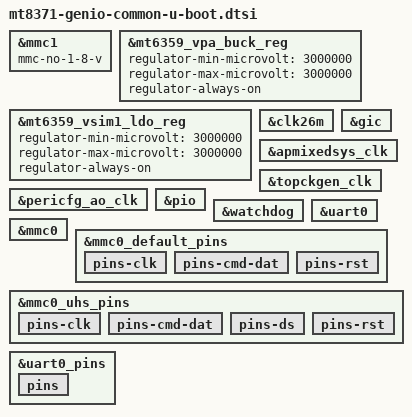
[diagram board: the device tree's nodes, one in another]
// SPDX-License-Identifier: (GPL-2.0-only OR MIT)
/*
 * Copyright (C) 2026 MediaTek Inc.
 */

&mmc1 {
	/* U-Boot driver doesn't support UHS yet. */
	/delete-property/ sd-uhs-sdr50;
	/delete-property/ sd-uhs-sdr104;
	mmc-no-1-8-v;
};

/*
 * Needed to trigger U-Boot auto-set-voltage. Default voltages for these
 * supplies at boot are incorrect and U-Boot MMC drivers don't set them.
 */

&mt6359_vpa_buck_reg {
	regulator-min-microvolt = <3000000>;
	regulator-max-microvolt = <3000000>;
	regulator-always-on;
};

&mt6359_vsim1_ldo_reg {
	regulator-min-microvolt = <3000000>;
	regulator-max-microvolt = <3000000>;
	regulator-always-on;
};

&clk26m {
	bootph-pre-ram;
};

&gic {
	/* Retain the eMMC interrupt parent even though SPL uses polling. */
	bootph-pre-ram;
};

&apmixedsys_clk {
	bootph-pre-ram;
};

&topckgen_clk {
	bootph-pre-ram;
};

&pericfg_ao_clk {
	bootph-pre-ram;
};

&pio {
	bootph-pre-ram;
};

&watchdog {
	bootph-pre-ram;
};

&uart0 {
	bootph-pre-ram;
};

&mmc0 {
	bootph-pre-ram;
};

&mmc0_default_pins {
	bootph-pre-ram;

	pins-clk {
		bootph-pre-ram;
	};

	pins-cmd-dat {
		bootph-pre-ram;
	};

	pins-rst {
		bootph-pre-ram;
	};
};

&mmc0_uhs_pins {
	bootph-pre-ram;

	pins-clk {
		bootph-pre-ram;
	};

	pins-cmd-dat {
		bootph-pre-ram;
	};

	pins-ds {
		bootph-pre-ram;
	};

	pins-rst {
		bootph-pre-ram;
	};
};

&uart0_pins {
	bootph-pre-ram;

	pins {
		bootph-pre-ram;
	};
};
